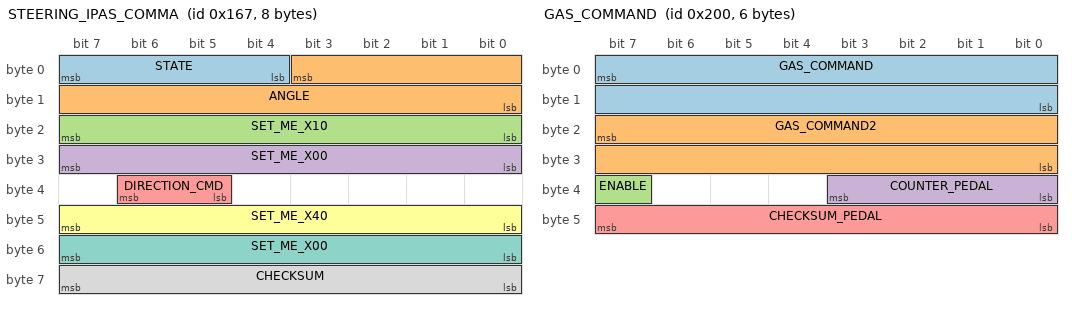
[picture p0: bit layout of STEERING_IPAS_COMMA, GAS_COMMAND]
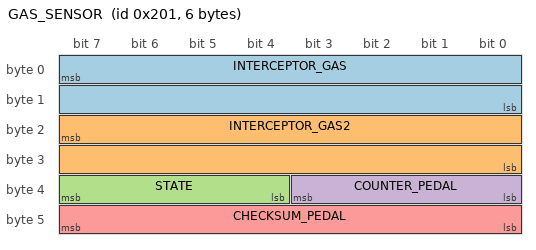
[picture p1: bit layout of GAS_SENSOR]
BO_ 359 STEERING_IPAS_COMMA: 8 IPAS
 SG_ STATE : 7|4@0+ (1,0) [0|15] "" XXX
 SG_ ANGLE : 3|12@0- (1.5,0) [-510|510] "deg" XXX
 SG_ SET_ME_X10 : 23|8@0+ (1,0) [0|255] "" XXX
 SG_ SET_ME_X00 : 31|8@0+ (1,0) [0|255] "" XXX
 SG_ DIRECTION_CMD : 38|2@0+ (1,0) [0|3] "" XXX
 SG_ SET_ME_X40 : 47|8@0+ (1,0) [0|255] "" XXX
 SG_ SET_ME_X00 : 55|8@0+ (1,0) [0|255] "" XXX
 SG_ CHECKSUM : 63|8@0+ (1,0) [0|255] "" XXX

CM BO_ STEERING_IPAS_COMMA "Copy of msg 614 so we can do angle control while the Park Assist ECU is connected (Panda spoofs 614 with 359 on connector J70). Note that addresses 0x266 and 0x167 are checksum-invariant";

 BO_ 512 GAS_COMMAND: 6 EON
  SG_ GAS_COMMAND : 7|16@0+ (0.159375,-75.555) [0|1] "" INTERCEPTOR
  SG_ GAS_COMMAND2 : 23|16@0+ (0.159375,-151.111) [0|1] "" INTERCEPTOR
  SG_ ENABLE : 39|1@0+ (1,0) [0|1] "" INTERCEPTOR
  SG_ COUNTER_PEDAL : 35|4@0+ (1,0) [0|15] "" INTERCEPTOR
  SG_ CHECKSUM_PEDAL : 47|8@0+ (1,0) [0|255] "" INTERCEPTOR

 BO_ 513 GAS_SENSOR: 6 INTERCEPTOR
  SG_ INTERCEPTOR_GAS : 7|16@0+ (0.159375,-75.555) [0|1] "" EON
  SG_ INTERCEPTOR_GAS2 : 23|16@0+ (0.159375,-151.111) [0|1] "" EON
  SG_ STATE : 39|4@0+ (1,0) [0|15] "" EON
  SG_ COUNTER_PEDAL : 35|4@0+ (1,0) [0|15] "" EON
  SG_ CHECKSUM_PEDAL : 47|8@0+ (1,0) [0|255] "" EON

 BO_ 515 OPENPILOT_BUTTONS: 8 XXX
  SG_ ACC_TIME_GAP : 1|2@0+ (1,0) [0|1] "" XXX

CM_ SG_ 515 ACC_TIME_GAP "acc time gap button press commanded by https://github.com/rhinodavid/OpenpilotButtons";

 VAL_ 513 STATE 5 "FAULT_TIMEOUT" 4 "FAULT_STARTUP" 3 "FAULT_SCE" 2 "FAULT_SEND" 1 "FAULT_BAD_CHECKSUM" 0 "NO_FAULT" ;
